# NAVSS0_BCDMA_0_ALIAS64K_BCDMA0_CFG_RING register map
Vendor: Texas Instruments
Peripheral module from a debugger description file (folder J721S2).
Registers are 32-bit, read-write, reset 0x0 unless marked. A register's access mark holds for its fields unless they carry their own. Offsets are as the file gives them; lines under a group give offsets from that group; [hi:lo] are bit positions; {n}, {i} and the like mark numbered series; 'fields as' and 'values as' point back to an identical list; <NAME> marks a mode.

## NAVSS0_BCDMA_0_ALIAS64K_BCDMA0_CFG_RING
0x40 ALIAS64K_BCDMA0__CFG__RING_BA_LO — The Ring Base Address Lo Register contains the 32 LSBs of the base address for the ring which is used to hand off pending work for the channel from the Host. The base address must be aligned to 0x8. A write to this register will reset the associated ring to clear the occupancies and reset the pointers.
  [31:0] ADDR_LO — Ring base address (LSBs)
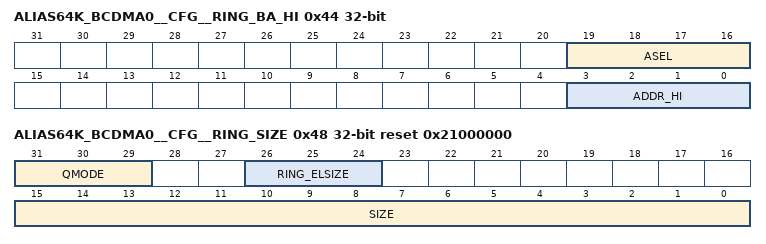
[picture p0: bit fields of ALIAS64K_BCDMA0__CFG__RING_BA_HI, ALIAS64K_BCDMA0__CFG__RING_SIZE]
0x44 ALIAS64K_BCDMA0__CFG__RING_BA_HI — The Ring Base Address Hi Register contains the 16 MSBs of the base address for the ring which is used to hand off pending work for the channel from the Host. The base address must be aligned to 0x8. A write to this register will reset the associated ring to clear the occupancies and reset the pointers.
  [19:16] ASEL — Ring base address select
  [3:0] ADDR_HI — Ring base address (MSBs)
0x48 ALIAS64K_BCDMA0__CFG__RING_SIZE access not given reset 0x21000000 — The Ring Size Register contains the element count for the ring which is used to hand off pending work for the channel from the Host. A write to this register will reset the associated ring to clear the occupancies and reset the pointers.
  [31:29] QMODE — Defines the mode for this ring or queue. (access R/NA)
  [26:24] RING_ELSIZE — (access R/NA)
  [15:0] SIZE rw — Tx Ring element count. This field configures the size of the ring in elements.
